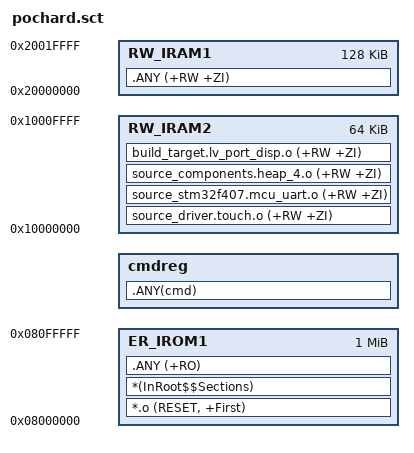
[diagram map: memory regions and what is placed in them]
; *************************************************************
; *** Scatter-Loading Description File generated by uVision ***
; *************************************************************

LR_IROM1 0x08000000 0x00100000  {    ; load region size_region
  ER_IROM1 0x08000000 0x00100000  {  ; load address = execution address
   *.o (RESET, +First)
   *(InRoot$$Sections)
   .ANY (+RO)
  }
  cmdreg +0
  {
	.ANY(cmd)
  }
  RW_IRAM1 0x20000000 0x00020000  {  ; RW data
   .ANY (+RW +ZI)
  }
;只能内核使用，DMA不能使用
	RW_IRAM2 0x10000000 0x00010000  {
   source_driver.touch.o (+RW +ZI)
   source_stm32f407.mcu_uart.o (+RW +ZI)
   source_components.heap_4.o (+RW +ZI)
   build_target.lv_port_disp.o (+RW +ZI)
  }
}

